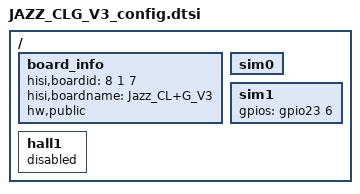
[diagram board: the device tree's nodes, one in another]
/*
 * Hisilicon Ltd.
 *
 * A15x4 A7x4
 *
 * It is only a demo for hisilicon hi3630 board. You show change the
 * address of each node according to datasheet.
 */



/include/ "JAZZ_CLG_V1_config.dtsi"
/include/ "hisi_3630_pin_JAZZ_CLG_V3.dtsi"
/include/ "hisi_3630_modem_JAZZ_CLG_V3.dtsi"
/ {
	board_info: board_info {
		hisi,boardid = <8 1 7>;
		hisi,boardname = "Jazz_CL+G_V3";
		hw,public;
	};
	sim0 {
		status = "ok";
	};
	sim1 {
		gpios = <&gpio23 6 0>;
		status = "ok";
	};

	hall1 {
		status = "disabled";
	};
};
